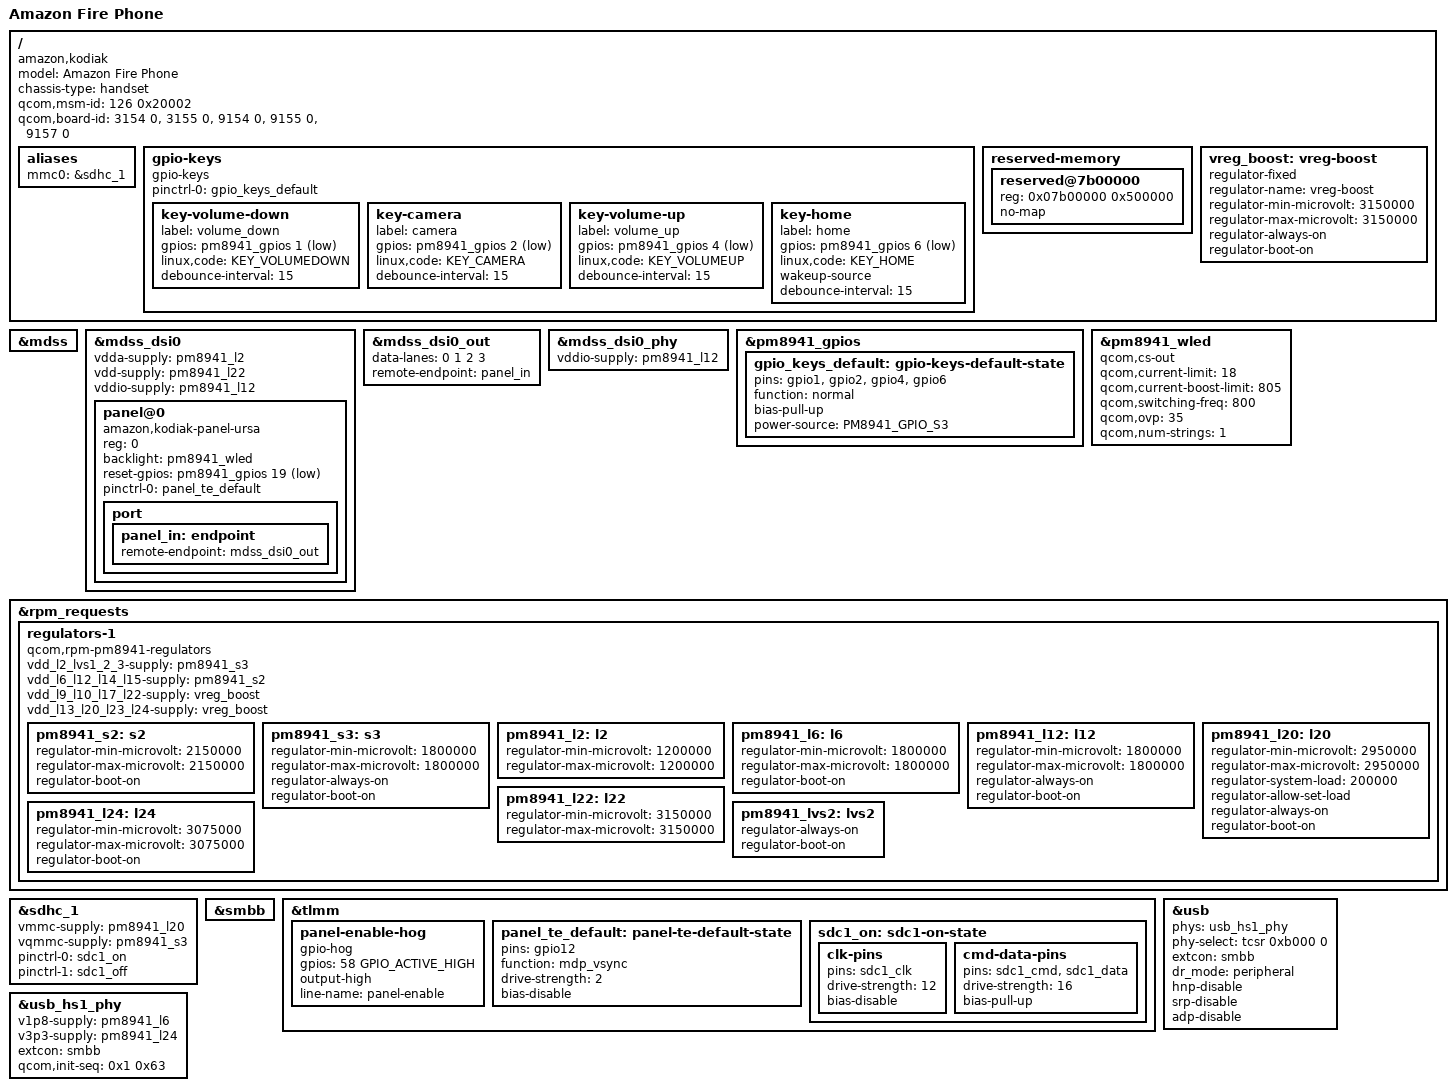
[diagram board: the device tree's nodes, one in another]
// SPDX-License-Identifier: GPL-2.0
#include "qcom-msm8974.dtsi"
#include "pm8841.dtsi"
#include "pm8941.dtsi"
#include <dt-bindings/input/input.h>
#include <dt-bindings/pinctrl/qcom,pmic-gpio.h>

/ {
	model = "Amazon Fire Phone";
	compatible = "amazon,kodiak", "qcom,msm8974";
	chassis-type = "handset";

	qcom,msm-id = <126 0x20002>;
	qcom,board-id = <3154 0>, <3155 0>, <9154 0>, <9155 0>, <9157 0>;

	aliases {
		mmc0 = &sdhc_1;
	};

	gpio-keys {
		compatible = "gpio-keys";

		pinctrl-names = "default";
		pinctrl-0 = <&gpio_keys_default>;

		key-volume-down {
			label = "volume_down";
			gpios = <&pm8941_gpios 1 GPIO_ACTIVE_LOW>;
			linux,code = <KEY_VOLUMEDOWN>;
			debounce-interval = <15>;
		};

		key-camera {
			label = "camera";
			gpios = <&pm8941_gpios 2 GPIO_ACTIVE_LOW>;
			linux,code = <KEY_CAMERA>;
			debounce-interval = <15>;
		};

		key-volume-up {
			label = "volume_up";
			gpios = <&pm8941_gpios 4 GPIO_ACTIVE_LOW>;
			linux,code = <KEY_VOLUMEUP>;
			debounce-interval = <15>;
		};

		key-home {
			label = "home";
			gpios = <&pm8941_gpios 6 GPIO_ACTIVE_LOW>;
			linux,code = <KEY_HOME>;
			wakeup-source;
			debounce-interval = <15>;
		};
	};

	reserved-memory {
		reserved@7b00000 {
			reg = <0x07b00000 0x500000>;
			no-map;
		};
	};

	vreg_boost: vreg-boost {
		compatible = "regulator-fixed";

		regulator-name = "vreg-boost";
		regulator-min-microvolt = <3150000>;
		regulator-max-microvolt = <3150000>;

		regulator-always-on;
		regulator-boot-on;
	};
};

&mdss {
	status = "okay";
};

&mdss_dsi0 {
	vdda-supply = <&pm8941_l2>;
	vdd-supply = <&pm8941_l22>;
	vddio-supply = <&pm8941_l12>;

	status = "okay";

	panel@0 {
		compatible = "amazon,kodiak-panel-ursa";
		reg = <0>;

		backlight = <&pm8941_wled>;
		reset-gpios = <&pm8941_gpios 19 GPIO_ACTIVE_LOW>;

		pinctrl-0 = <&panel_te_default>;
		pinctrl-names = "default";

		port {
			panel_in: endpoint {
				remote-endpoint = <&mdss_dsi0_out>;
			};
		};
	};
};

&mdss_dsi0_out {
	data-lanes = <0 1 2 3>;
	remote-endpoint = <&panel_in>;
};

&mdss_dsi0_phy {
	vddio-supply = <&pm8941_l12>;

	status = "okay";
};

&pm8941_gpios {
	gpio_keys_default: gpio-keys-default-state {
		pins = "gpio1", "gpio2", "gpio4", "gpio6";
		function = "normal";

		bias-pull-up;
		power-source = <PM8941_GPIO_S3>;
	};
};

&pm8941_wled {
	qcom,cs-out;
	qcom,current-limit = <18>;
	qcom,current-boost-limit = <805>;
	qcom,switching-freq = <800>;
	qcom,ovp = <35>;
	qcom,num-strings = <1>;

	status = "okay";
};

&rpm_requests {
	regulators-1 {
		compatible = "qcom,rpm-pm8941-regulators";

		vdd_l2_lvs1_2_3-supply = <&pm8941_s3>;
		vdd_l6_l12_l14_l15-supply = <&pm8941_s2>;
		vdd_l9_l10_l17_l22-supply = <&vreg_boost>;
		vdd_l13_l20_l23_l24-supply = <&vreg_boost>;

		pm8941_s2: s2 {
			regulator-min-microvolt = <2150000>;
			regulator-max-microvolt = <2150000>;
			regulator-boot-on;
		};

		pm8941_s3: s3 {
			regulator-min-microvolt = <1800000>;
			regulator-max-microvolt = <1800000>;
			regulator-always-on;
			regulator-boot-on;
		};

		pm8941_l2: l2 {
			regulator-min-microvolt = <1200000>;
			regulator-max-microvolt = <1200000>;
		};

		pm8941_l6: l6 {
			regulator-min-microvolt = <1800000>;
			regulator-max-microvolt = <1800000>;
			regulator-boot-on;
		};

		pm8941_l12: l12 {
			regulator-min-microvolt = <1800000>;
			regulator-max-microvolt = <1800000>;
			regulator-always-on;
			regulator-boot-on;
		};

		pm8941_l20: l20 {
			regulator-min-microvolt = <2950000>;
			regulator-max-microvolt = <2950000>;
			regulator-system-load = <200000>;
			regulator-allow-set-load;
			regulator-always-on;
			regulator-boot-on;
		};

		pm8941_l22: l22 {
			regulator-min-microvolt = <3150000>;
			regulator-max-microvolt = <3150000>;
		};

		pm8941_l24: l24 {
			regulator-min-microvolt = <3075000>;
			regulator-max-microvolt = <3075000>;
			regulator-boot-on;
		};

		pm8941_lvs2: lvs2 {
			regulator-always-on;
			regulator-boot-on;
		};
	};
};

&sdhc_1 {
	status = "okay";

	vmmc-supply = <&pm8941_l20>;
	vqmmc-supply = <&pm8941_s3>;

	pinctrl-names = "default", "sleep";
	pinctrl-0 = <&sdc1_on>;
	pinctrl-1 = <&sdc1_off>;
};

&smbb {
	status = "okay";
};

&tlmm {
	panel-enable-hog {
		gpio-hog;
		gpios = <58 GPIO_ACTIVE_HIGH>;
		output-high;
		line-name = "panel-enable";
	};

	panel_te_default: panel-te-default-state {
		pins = "gpio12";
		function = "mdp_vsync";
		drive-strength = <2>;
		bias-disable;
	};

	sdc1_on: sdc1-on-state {
		clk-pins {
			pins = "sdc1_clk";
			drive-strength = <12>;
			bias-disable;
		};

		cmd-data-pins {
			pins = "sdc1_cmd", "sdc1_data";
			drive-strength = <16>;
			bias-pull-up;
		};
	};
};

&usb {
	status = "okay";

	phys = <&usb_hs1_phy>;
	phy-select = <&tcsr 0xb000 0>;
	extcon = <&smbb>;
	dr_mode = "peripheral";

	hnp-disable;
	srp-disable;
	adp-disable;
};

&usb_hs1_phy {
	status = "okay";

	v1p8-supply = <&pm8941_l6>;
	v3p3-supply = <&pm8941_l24>;

	extcon = <&smbb>;
	qcom,init-seq = /bits/ 8 <0x1 0x63>;
};
